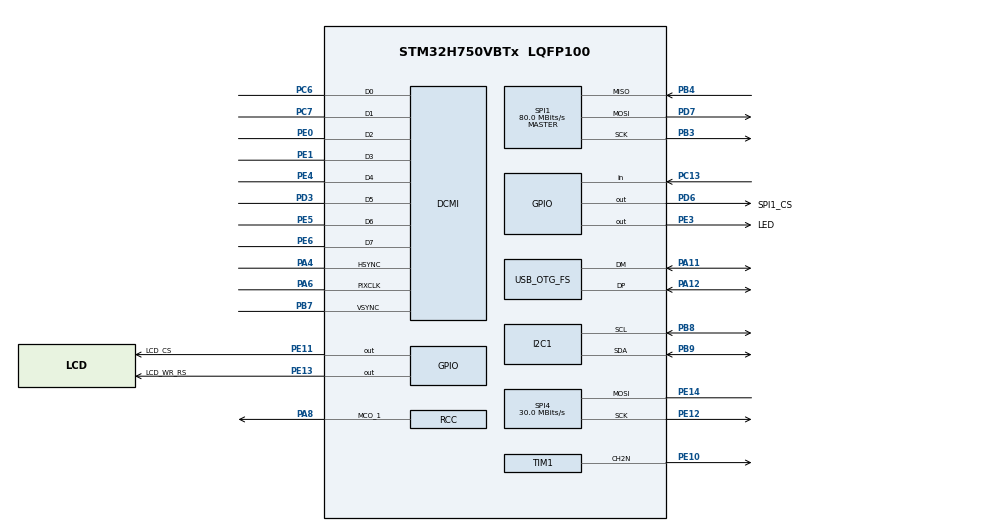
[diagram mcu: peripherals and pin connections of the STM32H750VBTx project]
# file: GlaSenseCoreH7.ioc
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CORTEX_M7.CPU_DCache=Enabled
CORTEX_M7.CPU_ICache=Enabled
CORTEX_M7.Enable-Cortex_Memory_Protection_Unit_Region0_Settings=MPU_REGION_ENABLE
CORTEX_M7.IsCacheable-Cortex_Memory_Protection_Unit_Region0_Settings=MPU_ACCESS_NOT_CACHEABLE
CORTEX_M7.MPU_Control=__NULL
DCMI.JPEGMode=DCMI_JPEG_DISABLE
DCMI.PCKPolarity=DCMI_PCKPOLARITY_RISING
Dma.DCMI.3.Direction=DMA_PERIPH_TO_MEMORY
Dma.DCMI.3.EventEnable=DISABLE
Dma.DCMI.3.FIFOMode=DMA_FIFOMODE_DISABLE
Dma.DCMI.3.Instance=DMA1_Stream0
Dma.DCMI.3.MemDataAlignment=DMA_MDATAALIGN_WORD
Dma.DCMI.3.MemInc=DMA_MINC_ENABLE
Dma.DCMI.3.Mode=DMA_NORMAL
Dma.DCMI.3.PeriphDataAlignment=DMA_PDATAALIGN_WORD
Dma.DCMI.3.PeriphInc=DMA_PINC_DISABLE
Dma.DCMI.3.Polarity=HAL_DMAMUX_REQ_GEN_RISING
Dma.DCMI.3.Priority=DMA_PRIORITY_LOW
Dma.DCMI.3.RequestNumber=1
Dma.DCMI.3.SignalID=NONE
Dma.DCMI.3.SyncEnable=DISABLE
Dma.DCMI.3.SyncPolarity=HAL_DMAMUX_SYNC_NO_EVENT
Dma.DCMI.3.SyncRequestNumber=1
Dma.DCMI.3.SyncSignalID=NONE
Dma.I2C1_RX.0.Direction=DMA_PERIPH_TO_MEMORY
Dma.I2C1_RX.0.EventEnable=DISABLE
Dma.I2C1_RX.0.FIFOMode=DMA_FIFOMODE_DISABLE
Dma.I2C1_RX.0.Instance=DMA1_Stream4
Dma.I2C1_RX.0.MemDataAlignment=DMA_MDATAALIGN_BYTE
Dma.I2C1_RX.0.MemInc=DMA_MINC_ENABLE
Dma.I2C1_RX.0.Mode=DMA_NORMAL
Dma.I2C1_RX.0.PeriphDataAlignment=DMA_PDATAALIGN_BYTE
Dma.I2C1_RX.0.PeriphInc=DMA_PINC_DISABLE
Dma.I2C1_RX.0.Polarity=HAL_DMAMUX_REQ_GEN_RISING
Dma.I2C1_RX.0.Priority=DMA_PRIORITY_LOW
Dma.I2C1_RX.0.RequestNumber=1
Dma.I2C1_RX.0.SignalID=NONE
Dma.I2C1_RX.0.SyncEnable=DISABLE
Dma.I2C1_RX.0.SyncPolarity=HAL_DMAMUX_SYNC_NO_EVENT
Dma.I2C1_RX.0.SyncRequestNumber=1
Dma.I2C1_RX.0.SyncSignalID=NONE
Dma.I2C1_TX.1.Direction=DMA_MEMORY_TO_PERIPH
Dma.I2C1_TX.1.EventEnable=DISABLE
Dma.I2C1_TX.1.FIFOMode=DMA_FIFOMODE_DISABLE
Dma.I2C1_TX.1.Instance=DMA1_Stream1
Dma.I2C1_TX.1.MemDataAlignment=DMA_MDATAALIGN_BYTE
Dma.I2C1_TX.1.MemInc=DMA_MINC_ENABLE
Dma.I2C1_TX.1.Mode=DMA_NORMAL
Dma.I2C1_TX.1.PeriphDataAlignment=DMA_PDATAALIGN_BYTE
Dma.I2C1_TX.1.PeriphInc=DMA_PINC_DISABLE
Dma.I2C1_TX.1.Polarity=HAL_DMAMUX_REQ_GEN_RISING
Dma.I2C1_TX.1.Priority=DMA_PRIORITY_LOW
Dma.I2C1_TX.1.RequestNumber=1
Dma.I2C1_TX.1.SignalID=NONE
Dma.I2C1_TX.1.SyncEnable=DISABLE
Dma.I2C1_TX.1.SyncPolarity=HAL_DMAMUX_SYNC_NO_EVENT
Dma.I2C1_TX.1.SyncRequestNumber=1
Dma.I2C1_TX.1.SyncSignalID=NONE
Dma.Request0=I2C1_RX
Dma.Request1=I2C1_TX
Dma.Request2=SPI4_TX
Dma.Request3=DCMI
Dma.Request4=SPI1_RX
Dma.Request5=SPI1_TX
Dma.SPI1_RX.4.Direction=DMA_PERIPH_TO_MEMORY
Dma.SPI1_RX.4.EventEnable=DISABLE
Dma.SPI1_RX.4.FIFOMode=DMA_FIFOMODE_DISABLE
Dma.SPI1_RX.4.Instance=DMA1_Stream2
Dma.SPI1_RX.4.MemDataAlignment=DMA_MDATAALIGN_BYTE
Dma.SPI1_RX.4.MemInc=DMA_MINC_ENABLE
Dma.SPI1_RX.4.Mode=DMA_NORMAL
Dma.SPI1_RX.4.PeriphDataAlignment=DMA_PDATAALIGN_BYTE
Dma.SPI1_RX.4.PeriphInc=DMA_PINC_DISABLE
Dma.SPI1_RX.4.Polarity=HAL_DMAMUX_REQ_GEN_RISING
Dma.SPI1_RX.4.Priority=DMA_PRIORITY_LOW
Dma.SPI1_RX.4.RequestNumber=1
Dma.SPI1_RX.4.SignalID=NONE
Dma.SPI1_RX.4.SyncEnable=DISABLE
Dma.SPI1_RX.4.SyncPolarity=HAL_DMAMUX_SYNC_NO_EVENT
Dma.SPI1_RX.4.SyncRequestNumber=1
Dma.SPI1_RX.4.SyncSignalID=NONE
Dma.SPI1_TX.5.Direction=DMA_MEMORY_TO_PERIPH
Dma.SPI1_TX.5.EventEnable=DISABLE
Dma.SPI1_TX.5.FIFOMode=DMA_FIFOMODE_DISABLE
Dma.SPI1_TX.5.Instance=DMA1_Stream5
Dma.SPI1_TX.5.MemDataAlignment=DMA_MDATAALIGN_BYTE
Dma.SPI1_TX.5.MemInc=DMA_MINC_ENABLE
Dma.SPI1_TX.5.Mode=DMA_NORMAL
Dma.SPI1_TX.5.PeriphDataAlignment=DMA_PDATAALIGN_BYTE
Dma.SPI1_TX.5.PeriphInc=DMA_PINC_DISABLE
Dma.SPI1_TX.5.Polarity=HAL_DMAMUX_REQ_GEN_RISING
Dma.SPI1_TX.5.Priority=DMA_PRIORITY_LOW
Dma.SPI1_TX.5.RequestNumber=1
Dma.SPI1_TX.5.SignalID=NONE
Dma.SPI1_TX.5.SyncEnable=DISABLE
Dma.SPI1_TX.5.SyncPolarity=HAL_DMAMUX_SYNC_NO_EVENT
Dma.SPI1_TX.5.SyncRequestNumber=1
Dma.SPI1_TX.5.SyncSignalID=NONE
Dma.SPI4_TX.2.Direction=DMA_MEMORY_TO_PERIPH
Dma.SPI4_TX.2.EventEnable=DISABLE
Dma.SPI4_TX.2.FIFOMode=DMA_FIFOMODE_DISABLE
Dma.SPI4_TX.2.Instance=DMA1_Stream3
Dma.SPI4_TX.2.MemDataAlignment=DMA_MDATAALIGN_BYTE
Dma.SPI4_TX.2.MemInc=DMA_MINC_ENABLE
Dma.SPI4_TX.2.Mode=DMA_NORMAL
Dma.SPI4_TX.2.PeriphDataAlignment=DMA_PDATAALIGN_BYTE
Dma.SPI4_TX.2.PeriphInc=DMA_PINC_DISABLE
Dma.SPI4_TX.2.Polarity=HAL_DMAMUX_REQ_GEN_RISING
Dma.SPI4_TX.2.Priority=DMA_PRIORITY_LOW
Dma.SPI4_TX.2.RequestNumber=1
Dma.SPI4_TX.2.SignalID=NONE
Dma.SPI4_TX.2.SyncEnable=DISABLE
Dma.SPI4_TX.2.SyncPolarity=HAL_DMAMUX_SYNC_NO_EVENT
Dma.SPI4_TX.2.SyncRequestNumber=1
Dma.SPI4_TX.2.SyncSignalID=NONE
FREERTOS.Tasks01=defaultTask,24,3192,StartDefaultTask,Default,NULL,Dynamic,NULL,NULL
FREERTOS.configCHECK_FOR_STACK_OVERFLOW=2
FREERTOS.configRECORD_STACK_HIGH_ADDRESS=1
FREERTOS.configTOTAL_HEAP_SIZE=50000
I2C1.I2C_Fall_Time=10
I2C1.I2C_Rise_Time=100
I2C1.Timing=0x40805E8A
Mcu.Family=STM32H7
Mcu.Name=STM32H750VBTx
Mcu.Package=LQFP100
NVIC.DCMI_IRQn=true\:5\:0\:false\:false\:true\:true\:true\:true\:true
NVIC.DMA1_Stream0_IRQn=true\:5\:0\:false\:false\:true\:true\:false\:true\:true
NVIC.DMA1_Stream1_IRQn=true\:5\:0\:false\:false\:true\:true\:false\:true\:true
NVIC.DMA1_Stream2_IRQn=true\:5\:0\:false\:false\:true\:true\:false\:true\:true
NVIC.DMA1_Stream3_IRQn=true\:5\:0\:false\:false\:true\:true\:false\:true\:true
NVIC.DMA1_Stream4_IRQn=true\:5\:0\:false\:false\:true\:true\:false\:true\:true
NVIC.DMA1_Stream5_IRQn=true\:5\:0\:false\:false\:true\:true\:false\:true\:true
NVIC.OTG_FS_EP1_IN_IRQn=true\:5\:0\:false\:false\:true\:true\:true\:true\:true
NVIC.OTG_FS_EP1_OUT_IRQn=true\:5\:0\:false\:false\:true\:true\:true\:true\:true
NVIC.OTG_FS_IRQn=true\:5\:0\:false\:false\:true\:true\:false\:true\:true
NVIC.PriorityGroup=NVIC_PRIORITYGROUP_4
NVIC.SPI1_IRQn=true\:5\:0\:false\:false\:true\:true\:false\:true\:true
NVIC.SPI4_IRQn=true\:5\:0\:false\:false\:true\:true\:false\:true\:true
NVIC.TIM16_IRQn=true\:5\:0\:false\:false\:true\:true\:true\:true\:true
NVIC.TIM17_IRQn=true\:15\:0\:false\:false\:true\:false\:false\:true\:true
NVIC.TimeBase=TIM17_IRQn
NVIC.TimeBaseIP=TIM17
PA11.Mode=Device_Only
PA11.Signal=USB_OTG_FS_DM
PA12.Mode=Device_Only
PA12.Signal=USB_OTG_FS_DP
PA13\ (JTMS/SWDIO).Mode=Serial_Wire
PA13\ (JTMS/SWDIO).Signal=DEBUG_JTMS-SWDIO
PA14\ (JTCK/SWCLK).Mode=Serial_Wire
PA14\ (JTCK/SWCLK).Signal=DEBUG_JTCK-SWCLK
PA4.Mode=Slave_8_bits_External_Synchro
PA4.Signal=DCMI_HSYNC
PA6.Mode=Slave_8_bits_External_Synchro
PA6.Signal=DCMI_PIXCLK
PA8.Mode=Clock-out-1
PA8.Signal=RCC_MCO_1
PB3\ (JTDO/TRACESWO).GPIO_Speed=GPIO_SPEED_FREQ_VERY_HIGH
PB3\ (JTDO/TRACESWO).Mode=Full_Duplex_Master
PB3\ (JTDO/TRACESWO).Signal=SPI1_SCK
PB4\ (NJTRST).GPIO_Speed=GPIO_SPEED_FREQ_VERY_HIGH
PB4\ (NJTRST).Mode=Full_Duplex_Master
PB4\ (NJTRST).Signal=SPI1_MISO
PB7.Mode=Slave_8_bits_External_Synchro
PB7.Signal=DCMI_VSYNC
PB8.GPIO_Pu=GPIO_PULLUP
PB8.Mode=I2C
PB8.Signal=I2C1_SCL
PB9.GPIO_Pu=GPIO_PULLUP
PB9.Mode=I2C
PB9.Signal=I2C1_SDA
PC13.GPIO_PuPd=GPIO_PULLDOWN
PC13.Signal=GPIO_Input
PC14-OSC32_IN\ (OSC32_IN).Mode=LSE-External-Oscillator
PC14-OSC32_IN\ (OSC32_IN).Signal=RCC_OSC32_IN
PC15-OSC32_OUT\ (OSC32_OUT).Mode=LSE-External-Oscillator
PC15-OSC32_OUT\ (OSC32_OUT).Signal=RCC_OSC32_OUT
PC6.Mode=Slave_8_bits_External_Synchro
PC6.Signal=DCMI_D0
PC7.Mode=Slave_8_bits_External_Synchro
PC7.Signal=DCMI_D1
PD3.Mode=Slave_8_bits_External_Synchro
PD3.Signal=DCMI_D5
PD6.GPIO_Label=SPI1_CS
PD6.Signal=GPIO_Output
PD7.GPIO_Speed=GPIO_SPEED_FREQ_VERY_HIGH
PD7.Mode=Full_Duplex_Master
PD7.Signal=SPI1_MOSI
PE0.Mode=Slave_8_bits_External_Synchro
PE0.Signal=DCMI_D2
PE1.Mode=Slave_8_bits_External_Synchro
PE1.Signal=DCMI_D3
PE10.Mode=PWM Generation2 CH2N
PE10.Signal=TIM1_CH2N
PE11.GPIO_Label=LCD_CS
PE11.Signal=GPIO_Output
PE12.GPIO_Speed=GPIO_SPEED_FREQ_VERY_HIGH
PE12.Mode=Simplex_Bidirectional_Master
PE12.Signal=SPI4_SCK
PE13.GPIO_Label=LCD_WR_RS
PE13.Signal=GPIO_Output
PE14.GPIO_Speed=GPIO_SPEED_FREQ_VERY_HIGH
PE14.Mode=Simplex_Bidirectional_Master
PE14.Signal=SPI4_MOSI
PE3.GPIO_Label=LED
PE3.Signal=GPIO_Output
PE4.Mode=Slave_8_bits_External_Synchro
PE4.Signal=DCMI_D4
PE5.Mode=Slave_8_bits_External_Synchro
PE5.Signal=DCMI_D6
PE6.Mode=Slave_8_bits_External_Synchro
PE6.Signal=DCMI_D7
PH0-OSC_IN\ (PH0).Mode=HSE-External-Oscillator
PH0-OSC_IN\ (PH0).Signal=RCC_OSC_IN
PH1-OSC_OUT\ (PH1).Mode=HSE-External-Oscillator
PH1-OSC_OUT\ (PH1).Signal=RCC_OSC_OUT
ProjectManager.HeapSize=0x200
ProjectManager.StackSize=0x400
ProjectManager.TargetToolchain=CMake
RCC.ADCFreq_Value=80000000
RCC.APB1Freq_Value=120000000
RCC.APB2Freq_Value=120000000
RCC.APB3Freq_Value=120000000
RCC.APB4Freq_Value=120000000
RCC.CortexFreq_Value=480000000
RCC.D1PPRE=RCC_APB3_DIV2
RCC.D2PPRE1=RCC_APB1_DIV2
RCC.D2PPRE2=RCC_APB2_DIV2
RCC.D3PPRE=RCC_APB4_DIV2
RCC.DIVM1=5
RCC.DIVM2=5
RCC.DIVM3=5
RCC.DIVN1=192
RCC.DIVN2=32
RCC.DIVN3=64
RCC.DIVQ1=20
RCC.DIVR1=4
RCC.HCLKFreq_Value=240000000
RCC.HPRE=RCC_HCLK_DIV2
RCC.HSE_VALUE=25000000
RCC.PLLFRACN=0
RCC.PLLSourceVirtual=RCC_PLLSOURCE_HSE
RCC.ProductRev=revV
RCC.RCC_MCO1Source=RCC_MCO1SOURCE_HSI48
RCC.RCC_MCODiv1=RCC_MCODIV_4
RCC.SPI123CLockSelection=RCC_SPI123CLKSOURCE_PLL3
RCC.SYSCLKFreq_VALUE=480000000
RCC.SYSCLKSource=RCC_SYSCLKSOURCE_PLLCLK
RCC.USBFreq_Value=48000000
SPI1.BaudRatePrescaler=SPI_BAUDRATEPRESCALER_2
SPI1.CalculateBaudRate=80.0 MBits/s
SPI1.DataSize=SPI_DATASIZE_8BIT
SPI1.Direction=SPI_DIRECTION_2LINES
SPI1.Mode=SPI_MODE_MASTER
SPI1.VirtualType=VM_MASTER
SPI4.BaudRatePrescaler=SPI_BAUDRATEPRESCALER_4
SPI4.CalculateBaudRate=30.0 MBits/s
SPI4.DataSize=SPI_DATASIZE_8BIT
SPI4.Direction=SPI_DIRECTION_1LINE
SPI4.Mode=SPI_MODE_MASTER
SPI4.VirtualType=VM_MASTER
TIM1.Channel-PWM\ Generation2\ CH2N=TIM_CHANNEL_2
TIM1.OCNPolarity_2=TIM_OCNPOLARITY_LOW
TIM1.Period=1000-1
TIM1.Prescaler=24-1
TIM16.Period=100-1
TIM16.Prescaler=240-1
USB_DEVICE.CLASS_NAME_FS=CDC
USB_DEVICE.VirtualMode-CDC_FS=Cdc
USB_DEVICE.VirtualModeFS=Cdc_FS
USB_OTG_FS.VirtualMode=Device_Only
VP_FREERTOS_VS_CMSIS_V2.Mode=CMSIS_V2
VP_MEMORYMAP_VS_MEMORYMAP.Mode=CurAppReg
VP_RNG_VS_RNG.Mode=RNG_Activate
VP_SYS_VS_tim17.Mode=TIM17
VP_TIM16_VS_ClockSourceINT.Mode=Enable_Timer
VP_USB_DEVICE_VS_USB_DEVICE_CDC_FS.Mode=CDC_FS
board=custom

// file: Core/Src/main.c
/* USER CODE BEGIN Header */
/**
 ******************************************************************************
 * @file           : main.c
 * @brief          : Main program body
 ******************************************************************************
 * @attention
 *
 * Copyright (c) 2025 STMicroelectronics.
 * All rights reserved.
 *
 * This software is licensed under terms that can be found in the LICENSE file
 * in the root directory of this software component.
 * If no LICENSE file comes with this software, it is provided AS-IS.
 *
 ******************************************************************************
 */
/* USER CODE END Header */
#include "main.h"
#include "cmsis_os.h"
#include "dcmi.h"
#include "dma.h"
#include "i2c.h"
#include "rng.h"
#include "spi.h"
#include "tim.h"
#include "usb_device.h"
#include "gpio.h"

void SystemClock_Config(void);
void MX_FREERTOS_Init(void);

int main(void)
{

  /* USER CODE BEGIN 1 */
  if ((uint32_t)(main) > QSPI_BASE)
  {
    for (uint8_t i = 0; i < 8; i++)
    {
      NVIC->ICER[i] = 0xFFFFFFFF;
      NVIC->ICPR[i] = 0xFFFFFFFF;
    }
    SCB->VTOR = QSPI_BASE;
    __enable_irq();
    __set_PRIMASK(0);
  }
  /* USER CODE END 1 */

  /* Enable the CPU Cache */

  /* Enable I-Cache---------------------------------------------------------*/
  SCB_EnableICache();

  /* Enable D-Cache---------------------------------------------------------*/
  SCB_EnableDCache();

  /* MCU Configuration--------------------------------------------------------*/

  /* Reset of all peripherals, Initializes the Flash interface and the Systick. */
  HAL_Init();

  /* Configure the system clock */
  SystemClock_Config();

  /* Initialize all configured peripherals */
  MX_GPIO_Init();
  MX_DMA_Init();
  MX_RNG_Init();
  MX_I2C1_Init();
  MX_SPI4_Init();
  MX_TIM1_Init();
  MX_DCMI_Init();
  MX_TIM16_Init();
  MX_SPI1_Init();

  /* Init scheduler */
  osKernelInitialize();  /* Call init function for freertos objects (in cmsis_os2.c) */
  MX_FREERTOS_Init();

  /* Start scheduler */
  osKernelStart();

  /* We should never get here as control is now taken by the scheduler */

  /* Infinite loop */
  while (1)
  {

  }
}

void SystemClock_Config(void)
{
  RCC_OscInitTypeDef RCC_OscInitStruct = {0};
  RCC_ClkInitTypeDef RCC_ClkInitStruct = {0};

  /** Supply configuration update enable
  */
  HAL_PWREx_ConfigSupply(PWR_LDO_SUPPLY);

  /** Configure the main internal regulator output voltage
  */
  __HAL_PWR_VOLTAGESCALING_CONFIG(PWR_REGULATOR_VOLTAGE_SCALE0);

  while(!__HAL_PWR_GET_FLAG(PWR_FLAG_VOSRDY)) {}

  /** Initializes the RCC Oscillators according to the specified parameters
  * in the RCC_OscInitTypeDef structure.
  */
  RCC_OscInitStruct.OscillatorType = RCC_OSCILLATORTYPE_HSI48|RCC_OSCILLATORTYPE_HSE;
  RCC_OscInitStruct.HSEState = RCC_HSE_ON;
  RCC_OscInitStruct.HSI48State = RCC_HSI48_ON;
  RCC_OscInitStruct.PLL.PLLState = RCC_PLL_ON;
  RCC_OscInitStruct.PLL.PLLSource = RCC_PLLSOURCE_HSE;
  RCC_OscInitStruct.PLL.PLLM = 5;
  RCC_OscInitStruct.PLL.PLLN = 192;
  RCC_OscInitStruct.PLL.PLLP = 2;
  RCC_OscInitStruct.PLL.PLLQ = 20;
  RCC_OscInitStruct.PLL.PLLR = 4;
  RCC_OscInitStruct.PLL.PLLRGE = RCC_PLL1VCIRANGE_2;
  RCC_OscInitStruct.PLL.PLLVCOSEL = RCC_PLL1VCOWIDE;
  RCC_OscInitStruct.PLL.PLLFRACN = 0;
  if (HAL_RCC_OscConfig(&RCC_OscInitStruct) != HAL_OK)
  {
    Error_Handler();
  }

  /** Initializes the CPU, AHB and APB buses clocks
  */
  RCC_ClkInitStruct.ClockType = RCC_CLOCKTYPE_HCLK|RCC_CLOCKTYPE_SYSCLK
                              |RCC_CLOCKTYPE_PCLK1|RCC_CLOCKTYPE_PCLK2
                              |RCC_CLOCKTYPE_D3PCLK1|RCC_CLOCKTYPE_D1PCLK1;
  RCC_ClkInitStruct.SYSCLKSource = RCC_SYSCLKSOURCE_PLLCLK;
  RCC_ClkInitStruct.SYSCLKDivider = RCC_SYSCLK_DIV1;
  RCC_ClkInitStruct.AHBCLKDivider = RCC_HCLK_DIV2;
  RCC_ClkInitStruct.APB3CLKDivider = RCC_APB3_DIV2;
  RCC_ClkInitStruct.APB1CLKDivider = RCC_APB1_DIV2;
  RCC_ClkInitStruct.APB2CLKDivider = RCC_APB2_DIV2;
  RCC_ClkInitStruct.APB4CLKDivider = RCC_APB4_DIV2;

  if (HAL_RCC_ClockConfig(&RCC_ClkInitStruct, FLASH_LATENCY_4) != HAL_OK)
  {
    Error_Handler();
  }
  HAL_RCC_MCOConfig(RCC_MCO1, RCC_MCO1SOURCE_HSI48, RCC_MCODIV_4);
}

void HAL_TIM_PeriodElapsedCallback(TIM_HandleTypeDef *htim)
{
  if (htim->Instance == TIM17)
  {
    HAL_IncTick();
  }
}

void Error_Handler(void)
{
  __disable_irq();
  while (1)
  {
  }
}

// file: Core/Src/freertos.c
/* USER CODE BEGIN Header */
/**
 ******************************************************************************
 * File Name          : freertos.c
 * Description        : Code for freertos applications
 ******************************************************************************
 * @attention
 *
 * Copyright (c) 2025 STMicroelectronics.
 * All rights reserved.
 *
 * This software is licensed under terms that can be found in the LICENSE file
 * in the root directory of this software component.
 * If no LICENSE file comes with this software, it is provided AS-IS.
 *
 ******************************************************************************
 */
/* USER CODE END Header */

#include "FreeRTOS.h"
#include "task.h"
#include "main.h"
#include "cmsis_os.h"

/* USER CODE BEGIN Includes */
#include "app_main.h"
/* USER CODE END Includes */

/* Definitions for defaultTask */
osThreadId_t defaultTaskHandle;
const osThreadAttr_t defaultTask_attributes = {
  .name = "defaultTask",
  .stack_size = 3192 * 4,
  .priority = (osPriority_t) osPriorityNormal,
};

void StartDefaultTask(void *argument);

extern void MX_USB_DEVICE_Init(void);
void MX_FREERTOS_Init(void); /* (MISRA C 2004 rule 8.1) */

/* Hook prototypes */
void vApplicationStackOverflowHook(xTaskHandle xTask, signed char *pcTaskName);

void MX_FREERTOS_Init(void) {

  /* Create the thread(s) */
  /* creation of defaultTask */
  defaultTaskHandle = osThreadNew(StartDefaultTask, NULL, &defaultTask_attributes);

}

void StartDefaultTask(void *argument)
{
  /* init code for USB_DEVICE */
  MX_USB_DEVICE_Init();
  /* USER CODE BEGIN StartDefaultTask */
  app_main();
  /* Infinite loop */
  for (;;) {
    osDelay(1);
  }
  /* USER CODE END StartDefaultTask */
}
